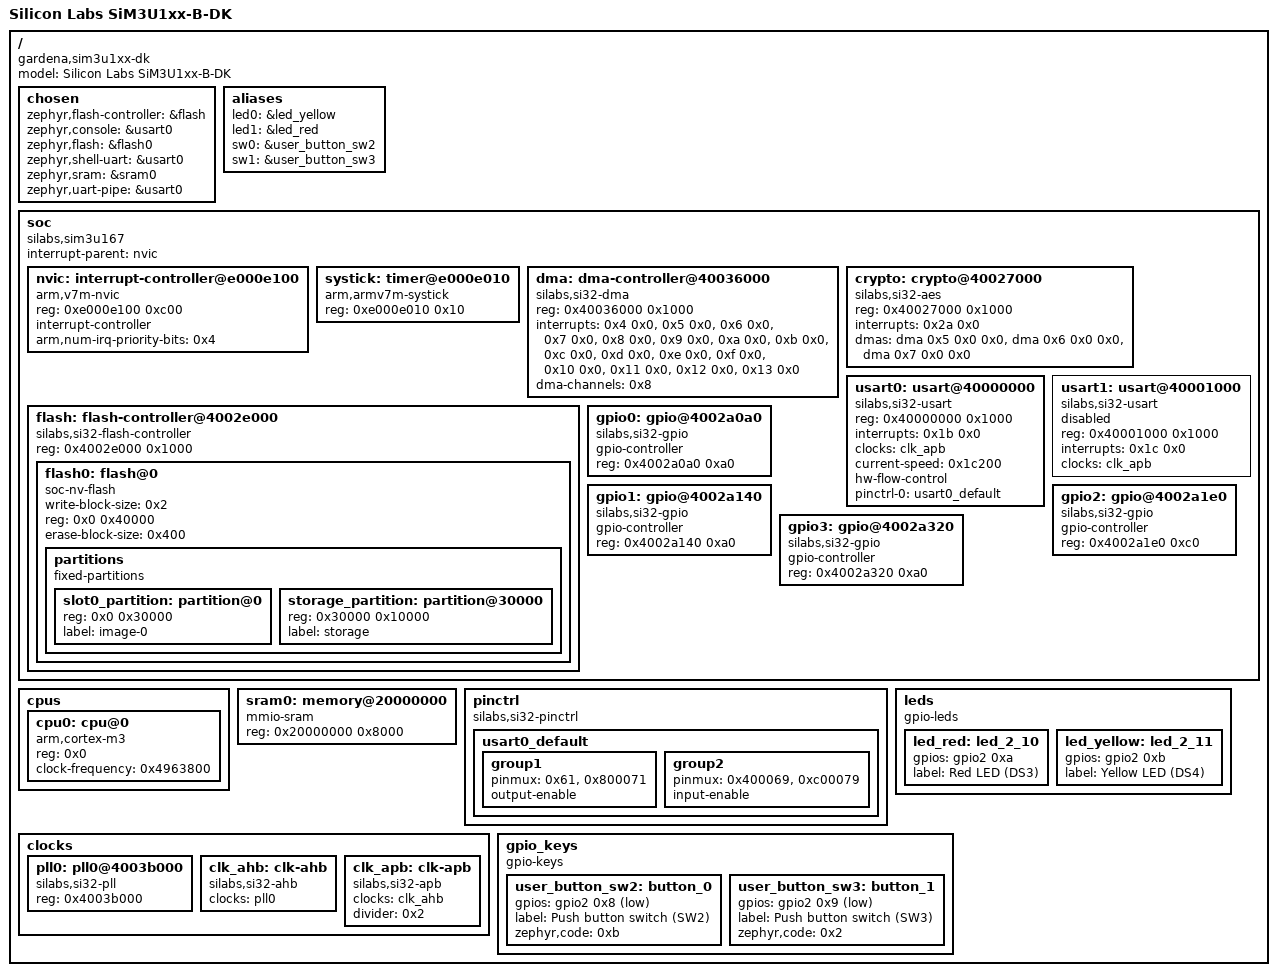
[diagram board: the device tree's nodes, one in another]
/dts-v1/;

/* node '/' defined in zephyr/dts/common/skeleton.dtsi:9 */
/ {
	#address-cells = < 0x1 >;             /* in zephyr/dts/common/skeleton.dtsi:10 */
	#size-cells = < 0x1 >;                /* in zephyr/dts/common/skeleton.dtsi:11 */
	model = "Silicon Labs SiM3U1xx-B-DK"; /* in zephyr/boards/silabs/dev_kits/sim3u1xx_dk/sim3u1xx_dk.dts:13 */
	compatible = "gardena,sim3u1xx-dk",
	             "silabs,sim3u167",
	             "silabs,sim3u";          /* in zephyr/boards/silabs/dev_kits/sim3u1xx_dk/sim3u1xx_dk.dts:14 */

	/* node '/chosen' defined in zephyr/dts/common/skeleton.dtsi:13 */
	chosen {
		zephyr,flash-controller = &flash; /* in zephyr/dts/arm/silabs/sim3u.dtsi:13 */
		zephyr,console = &usart0;         /* in zephyr/boards/silabs/dev_kits/sim3u1xx_dk/sim3u1xx_dk.dts:24 */
		zephyr,flash = &flash0;           /* in zephyr/boards/silabs/dev_kits/sim3u1xx_dk/sim3u1xx_dk.dts:25 */
		zephyr,shell-uart = &usart0;      /* in zephyr/boards/silabs/dev_kits/sim3u1xx_dk/sim3u1xx_dk.dts:26 */
		zephyr,sram = &sram0;             /* in zephyr/boards/silabs/dev_kits/sim3u1xx_dk/sim3u1xx_dk.dts:27 */
		zephyr,uart-pipe = &usart0;       /* in zephyr/boards/silabs/dev_kits/sim3u1xx_dk/sim3u1xx_dk.dts:28 */
	};

	/* node '/aliases' defined in zephyr/dts/common/skeleton.dtsi:15 */
	aliases {
		led0 = &led_yellow;     /* in zephyr/boards/silabs/dev_kits/sim3u1xx_dk/sim3u1xx_dk.dts:17 */
		led1 = &led_red;        /* in zephyr/boards/silabs/dev_kits/sim3u1xx_dk/sim3u1xx_dk.dts:18 */
		sw0 = &user_button_sw2; /* in zephyr/boards/silabs/dev_kits/sim3u1xx_dk/sim3u1xx_dk.dts:19 */
		sw1 = &user_button_sw3; /* in zephyr/boards/silabs/dev_kits/sim3u1xx_dk/sim3u1xx_dk.dts:20 */
	};

	/* node '/soc' defined in zephyr/dts/arm/armv7-m.dtsi:6 */
	soc {
		#address-cells = < 0x1 >;       /* in zephyr/dts/arm/armv7-m.dtsi:7 */
		#size-cells = < 0x1 >;          /* in zephyr/dts/arm/armv7-m.dtsi:8 */
		interrupt-parent = < &nvic >;   /* in zephyr/dts/arm/armv7-m.dtsi:10 */
		ranges;                         /* in zephyr/dts/arm/armv7-m.dtsi:11 */
		compatible = "silabs,sim3u167",
		             "silabs,sim3u",
		             "silabs,sim3",
		             "simple-bus";      /* in zephyr/dts/arm/silabs/sim3u167.dtsi:12 */

		/* node '/soc/interrupt-controller@e000e100' defined in zephyr/dts/arm/armv7-m.dtsi:13 */
		nvic: interrupt-controller@e000e100 {
			#address-cells = < 0x1 >;            /* in zephyr/dts/arm/armv7-m.dtsi:14 */
			compatible = "arm,v7m-nvic";         /* in zephyr/dts/arm/armv7-m.dtsi:15 */
			reg = < 0xe000e100 0xc00 >;          /* in zephyr/dts/arm/armv7-m.dtsi:16 */
			interrupt-controller;                /* in zephyr/dts/arm/armv7-m.dtsi:17 */
			#interrupt-cells = < 0x2 >;          /* in zephyr/dts/arm/armv7-m.dtsi:18 */
			arm,num-irq-priority-bits = < 0x4 >; /* in zephyr/dts/arm/silabs/sim3u.dtsi:147 */
			phandle = < 0x1 >;                   /* in zephyr/dts/arm/armv7-m.dtsi:10 */
		};

		/* node '/soc/timer@e000e010' defined in zephyr/dts/arm/armv7-m.dtsi:21 */
		systick: timer@e000e010 {
			compatible = "arm,armv7m-systick"; /* in zephyr/dts/arm/armv7-m.dtsi:22 */
			reg = < 0xe000e010 0x10 >;         /* in zephyr/dts/arm/armv7-m.dtsi:23 */
		};

		/* node '/soc/dma-controller@40036000' defined in zephyr/dts/arm/silabs/sim3u.dtsi:64 */
		dma: dma-controller@40036000 {
			compatible = "silabs,si32-dma"; /* in zephyr/dts/arm/silabs/sim3u.dtsi:65 */
			reg = < 0x40036000 0x1000 >;    /* in zephyr/dts/arm/silabs/sim3u.dtsi:66 */
			interrupts = < 0x4 0x0 >,
			             < 0x5 0x0 >,
			             < 0x6 0x0 >,
			             < 0x7 0x0 >,
			             < 0x8 0x0 >,
			             < 0x9 0x0 >,
			             < 0xa 0x0 >,
			             < 0xb 0x0 >,
			             < 0xc 0x0 >,
			             < 0xd 0x0 >,
			             < 0xe 0x0 >,
			             < 0xf 0x0 >,
			             < 0x10 0x0 >,
			             < 0x11 0x0 >,
			             < 0x12 0x0 >,
			             < 0x13 0x0 >;      /* in zephyr/dts/arm/silabs/sim3u.dtsi:67 */
			#dma-cells = < 0x3 >;           /* in zephyr/dts/arm/silabs/sim3u.dtsi:72 */
			dma-channels = < 0x8 >;         /* in zephyr/boards/silabs/dev_kits/sim3u1xx_dk/sim3u1xx_dk.dts:117 */
			status = "okay";                /* in zephyr/boards/silabs/dev_kits/sim3u1xx_dk/sim3u1xx_dk.dts:118 */
			phandle = < 0x2 >;              /* in zephyr/dts/arm/silabs/sim3u.dtsi:80 */
		};

		/* node '/soc/crypto@40027000' defined in zephyr/dts/arm/silabs/sim3u.dtsi:76 */
		crypto: crypto@40027000 {
			compatible = "silabs,si32-aes"; /* in zephyr/dts/arm/silabs/sim3u.dtsi:77 */
			reg = < 0x40027000 0x1000 >;    /* in zephyr/dts/arm/silabs/sim3u.dtsi:78 */
			interrupts = < 0x2a 0x0 >;      /* in zephyr/dts/arm/silabs/sim3u.dtsi:79 */
			dmas = < &dma 0x5 0x0 0x0 >,
			       < &dma 0x6 0x0 0x0 >,
			       < &dma 0x7 0x0 0x0 >;    /* in zephyr/dts/arm/silabs/sim3u.dtsi:80 */
			dma-names = "tx",
			            "rx",
			            "xor";              /* in zephyr/dts/arm/silabs/sim3u.dtsi:83 */
			status = "okay";                /* in zephyr/boards/silabs/dev_kits/sim3u1xx_dk/sim3u1xx_dk.dts:122 */
		};

		/* node '/soc/flash-controller@4002e000' defined in zephyr/dts/arm/silabs/sim3u.dtsi:87 */
		flash: flash-controller@4002e000 {
			compatible = "silabs,si32-flash-controller"; /* in zephyr/dts/arm/silabs/sim3u.dtsi:88 */
			reg = < 0x4002e000 0x1000 >;                 /* in zephyr/dts/arm/silabs/sim3u.dtsi:89 */
			#address-cells = < 0x1 >;                    /* in zephyr/dts/arm/silabs/sim3u.dtsi:91 */
			#size-cells = < 0x1 >;                       /* in zephyr/dts/arm/silabs/sim3u.dtsi:92 */

			/* node '/soc/flash-controller@4002e000/flash@0' defined in zephyr/dts/arm/silabs/sim3u.dtsi:94 */
			flash0: flash@0 {
				compatible = "soc-nv-flash";  /* in zephyr/dts/arm/silabs/sim3u.dtsi:95 */
				write-block-size = < 0x2 >;   /* in zephyr/dts/arm/silabs/sim3u.dtsi:96 */
				reg = < 0x0 0x40000 >;        /* in zephyr/dts/arm/silabs/sim3u167.dtsi:17 */
				erase-block-size = < 0x400 >; /* in zephyr/dts/arm/silabs/sim3u167.dtsi:18 */
				status = "okay";              /* in zephyr/boards/silabs/dev_kits/sim3u1xx_dk/sim3u1xx_dk.dts:97 */

				/* node '/soc/flash-controller@4002e000/flash@0/partitions' defined in zephyr/boards/silabs/dev_kits/sim3u1xx_dk/sim3u1xx_dk.dts:99 */
				partitions {
					compatible = "fixed-partitions"; /* in zephyr/boards/silabs/dev_kits/sim3u1xx_dk/sim3u1xx_dk.dts:100 */
					#address-cells = < 0x1 >;        /* in zephyr/boards/silabs/dev_kits/sim3u1xx_dk/sim3u1xx_dk.dts:101 */
					#size-cells = < 0x1 >;           /* in zephyr/boards/silabs/dev_kits/sim3u1xx_dk/sim3u1xx_dk.dts:102 */

					/* node '/soc/flash-controller@4002e000/flash@0/partitions/partition@0' defined in zephyr/boards/silabs/dev_kits/sim3u1xx_dk/sim3u1xx_dk.dts:104 */
					slot0_partition: partition@0 {
						reg = < 0x0 0x30000 >; /* in zephyr/boards/silabs/dev_kits/sim3u1xx_dk/sim3u1xx_dk.dts:105 */
						label = "image-0";     /* in zephyr/boards/silabs/dev_kits/sim3u1xx_dk/sim3u1xx_dk.dts:106 */
					};

					/* node '/soc/flash-controller@4002e000/flash@0/partitions/partition@30000' defined in zephyr/boards/silabs/dev_kits/sim3u1xx_dk/sim3u1xx_dk.dts:109 */
					storage_partition: partition@30000 {
						reg = < 0x30000 0x10000 >; /* in zephyr/boards/silabs/dev_kits/sim3u1xx_dk/sim3u1xx_dk.dts:110 */
						label = "storage";         /* in zephyr/boards/silabs/dev_kits/sim3u1xx_dk/sim3u1xx_dk.dts:111 */
					};
				};
			};
		};

		/* node '/soc/usart@40000000' defined in zephyr/dts/arm/silabs/sim3u.dtsi:100 */
		usart0: usart@40000000 {
			compatible = "silabs,si32-usart"; /* in zephyr/dts/arm/silabs/sim3u.dtsi:101 */
			reg = < 0x40000000 0x1000 >;      /* in zephyr/dts/arm/silabs/sim3u.dtsi:102 */
			interrupts = < 0x1b 0x0 >;        /* in zephyr/dts/arm/silabs/sim3u.dtsi:103 */
			clocks = < &clk_apb >;            /* in zephyr/dts/arm/silabs/sim3u.dtsi:104 */
			current-speed = < 0x1c200 >;      /* in zephyr/boards/silabs/dev_kits/sim3u1xx_dk/sim3u1xx_dk.dts:81 */
			hw-flow-control;                  /* in zephyr/boards/silabs/dev_kits/sim3u1xx_dk/sim3u1xx_dk.dts:82 */
			pinctrl-0 = < &usart0_default >;  /* in zephyr/boards/silabs/dev_kits/sim3u1xx_dk/sim3u1xx_dk.dts:83 */
			pinctrl-names = "default";        /* in zephyr/boards/silabs/dev_kits/sim3u1xx_dk/sim3u1xx_dk.dts:84 */
			status = "okay";                  /* in zephyr/boards/silabs/dev_kits/sim3u1xx_dk/sim3u1xx_dk.dts:85 */
		};

		/* node '/soc/usart@40001000' defined in zephyr/dts/arm/silabs/sim3u.dtsi:108 */
		usart1: usart@40001000 {
			compatible = "silabs,si32-usart"; /* in zephyr/dts/arm/silabs/sim3u.dtsi:109 */
			reg = < 0x40001000 0x1000 >;      /* in zephyr/dts/arm/silabs/sim3u.dtsi:110 */
			interrupts = < 0x1c 0x0 >;        /* in zephyr/dts/arm/silabs/sim3u.dtsi:111 */
			clocks = < &clk_apb >;            /* in zephyr/dts/arm/silabs/sim3u.dtsi:112 */
			status = "disabled";              /* in zephyr/dts/arm/silabs/sim3u.dtsi:113 */
		};

		/* node '/soc/gpio@4002a0a0' defined in zephyr/dts/arm/silabs/sim3u.dtsi:116 */
		gpio0: gpio@4002a0a0 {
			compatible = "silabs,si32-gpio"; /* in zephyr/dts/arm/silabs/sim3u.dtsi:117 */
			gpio-controller;                 /* in zephyr/dts/arm/silabs/sim3u.dtsi:118 */
			#gpio-cells = < 0x2 >;           /* in zephyr/dts/arm/silabs/sim3u.dtsi:119 */
			reg = < 0x4002a0a0 0xa0 >;       /* in zephyr/dts/arm/silabs/sim3u.dtsi:120 */
			status = "okay";                 /* in zephyr/boards/silabs/dev_kits/sim3u1xx_dk/sim3u1xx_dk.dts:89 */
		};

		/* node '/soc/gpio@4002a140' defined in zephyr/dts/arm/silabs/sim3u.dtsi:123 */
		gpio1: gpio@4002a140 {
			compatible = "silabs,si32-gpio"; /* in zephyr/dts/arm/silabs/sim3u.dtsi:124 */
			gpio-controller;                 /* in zephyr/dts/arm/silabs/sim3u.dtsi:125 */
			#gpio-cells = < 0x2 >;           /* in zephyr/dts/arm/silabs/sim3u.dtsi:126 */
			reg = < 0x4002a140 0xa0 >;       /* in zephyr/dts/arm/silabs/sim3u.dtsi:127 */
		};

		/* node '/soc/gpio@4002a1e0' defined in zephyr/dts/arm/silabs/sim3u.dtsi:130 */
		gpio2: gpio@4002a1e0 {
			compatible = "silabs,si32-gpio"; /* in zephyr/dts/arm/silabs/sim3u.dtsi:131 */
			gpio-controller;                 /* in zephyr/dts/arm/silabs/sim3u.dtsi:132 */
			#gpio-cells = < 0x2 >;           /* in zephyr/dts/arm/silabs/sim3u.dtsi:133 */
			reg = < 0x4002a1e0 0xc0 >;       /* in zephyr/dts/arm/silabs/sim3u.dtsi:134 */
			status = "okay";                 /* in zephyr/boards/silabs/dev_kits/sim3u1xx_dk/sim3u1xx_dk.dts:93 */
			phandle = < 0x7 >;               /* in zephyr/boards/silabs/dev_kits/sim3u1xx_dk/sim3u1xx_dk.dts:35 */
		};

		/* node '/soc/gpio@4002a320' defined in zephyr/dts/arm/silabs/sim3u.dtsi:137 */
		gpio3: gpio@4002a320 {
			compatible = "silabs,si32-gpio"; /* in zephyr/dts/arm/silabs/sim3u.dtsi:138 */
			gpio-controller;                 /* in zephyr/dts/arm/silabs/sim3u.dtsi:139 */
			#gpio-cells = < 0x2 >;           /* in zephyr/dts/arm/silabs/sim3u.dtsi:140 */
			reg = < 0x4002a320 0xa0 >;       /* in zephyr/dts/arm/silabs/sim3u.dtsi:141 */
		};
	};

	/* node '/cpus' defined in zephyr/dts/arm/silabs/sim3u.dtsi:16 */
	cpus {
		#address-cells = < 0x1 >; /* in zephyr/dts/arm/silabs/sim3u.dtsi:17 */
		#size-cells = < 0x0 >;    /* in zephyr/dts/arm/silabs/sim3u.dtsi:18 */

		/* node '/cpus/cpu@0' defined in zephyr/dts/arm/silabs/sim3u.dtsi:20 */
		cpu0: cpu@0 {
			compatible = "arm,cortex-m3";    /* in zephyr/dts/arm/silabs/sim3u.dtsi:21 */
			device_type = "cpu";             /* in zephyr/dts/arm/silabs/sim3u.dtsi:22 */
			reg = < 0x0 >;                   /* in zephyr/dts/arm/silabs/sim3u.dtsi:24 */
			clock-frequency = < 0x4963800 >; /* in zephyr/boards/silabs/dev_kits/sim3u1xx_dk/sim3u1xx_dk.dts:63 */
		};
	};

	/* node '/memory@20000000' defined in zephyr/dts/arm/silabs/sim3u.dtsi:28 */
	sram0: memory@20000000 {
		compatible = "mmio-sram";    /* in zephyr/dts/arm/silabs/sim3u.dtsi:29 */
		reg = < 0x20000000 0x8000 >; /* in zephyr/dts/arm/silabs/sim3u167.dtsi:22 */
	};

	/* node '/pinctrl' defined in zephyr/dts/arm/silabs/sim3u.dtsi:32 */
	pinctrl: pinctrl {
		compatible = "silabs,si32-pinctrl"; /* in zephyr/dts/arm/silabs/sim3u.dtsi:33 */
		status = "okay";                    /* in zephyr/dts/arm/silabs/sim3u.dtsi:34 */

		/* node '/pinctrl/usart0_default' defined in zephyr/boards/silabs/dev_kits/sim3u1xx_dk/sim3u1xx_dk-pinctrl.dtsi:10 */
		usart0_default: usart0_default {
			phandle = < 0x4 >; /* in zephyr/boards/silabs/dev_kits/sim3u1xx_dk/sim3u1xx_dk.dts:83 */

			/* node '/pinctrl/usart0_default/group1' defined in zephyr/boards/silabs/dev_kits/sim3u1xx_dk/sim3u1xx_dk-pinctrl.dtsi:11 */
			group1 {
				pinmux = < 0x61 >,
				         < 0x800071 >; /* in zephyr/boards/silabs/dev_kits/sim3u1xx_dk/sim3u1xx_dk-pinctrl.dtsi:12 */
				output-enable;         /* in zephyr/boards/silabs/dev_kits/sim3u1xx_dk/sim3u1xx_dk-pinctrl.dtsi:14 */
			};

			/* node '/pinctrl/usart0_default/group2' defined in zephyr/boards/silabs/dev_kits/sim3u1xx_dk/sim3u1xx_dk-pinctrl.dtsi:17 */
			group2 {
				pinmux = < 0x400069 >,
				         < 0xc00079 >; /* in zephyr/boards/silabs/dev_kits/sim3u1xx_dk/sim3u1xx_dk-pinctrl.dtsi:18 */
				input-enable;          /* in zephyr/boards/silabs/dev_kits/sim3u1xx_dk/sim3u1xx_dk-pinctrl.dtsi:20 */
			};
		};
	};

	/* node '/clocks' defined in zephyr/dts/arm/silabs/sim3u.dtsi:37 */
	clocks {
		#address-cells = < 0x1 >; /* in zephyr/dts/arm/silabs/sim3u.dtsi:38 */
		#size-cells = < 0x0 >;    /* in zephyr/dts/arm/silabs/sim3u.dtsi:39 */

		/* node '/clocks/pll0@4003b000' defined in zephyr/dts/arm/silabs/sim3u.dtsi:41 */
		pll0: pll0@4003b000 {
			compatible = "silabs,si32-pll"; /* in zephyr/dts/arm/silabs/sim3u.dtsi:42 */
			#clock-cells = < 0x0 >;         /* in zephyr/dts/arm/silabs/sim3u.dtsi:43 */
			reg = < 0x4003b000 >;           /* in zephyr/dts/arm/silabs/sim3u.dtsi:44 */
			status = "okay";                /* in zephyr/boards/silabs/dev_kits/sim3u1xx_dk/sim3u1xx_dk.dts:67 */
			phandle = < 0x5 >;              /* in zephyr/boards/silabs/dev_kits/sim3u1xx_dk/sim3u1xx_dk.dts:71 */
		};

		/* node '/clocks/clk-ahb' defined in zephyr/dts/arm/silabs/sim3u.dtsi:48 */
		clk_ahb: clk-ahb {
			compatible = "silabs,si32-ahb"; /* in zephyr/dts/arm/silabs/sim3u.dtsi:49 */
			#clock-cells = < 0x0 >;         /* in zephyr/dts/arm/silabs/sim3u.dtsi:50 */
			clocks = < &pll0 >;             /* in zephyr/boards/silabs/dev_kits/sim3u1xx_dk/sim3u1xx_dk.dts:71 */
			status = "okay";                /* in zephyr/boards/silabs/dev_kits/sim3u1xx_dk/sim3u1xx_dk.dts:72 */
			phandle = < 0x6 >;              /* in zephyr/dts/arm/silabs/sim3u.dtsi:58 */
		};

		/* node '/clocks/clk-apb' defined in zephyr/dts/arm/silabs/sim3u.dtsi:54 */
		clk_apb: clk-apb {
			compatible = "silabs,si32-apb"; /* in zephyr/dts/arm/silabs/sim3u.dtsi:55 */
			#clock-cells = < 0x0 >;         /* in zephyr/dts/arm/silabs/sim3u.dtsi:56 */
			clocks = < &clk_ahb >;          /* in zephyr/dts/arm/silabs/sim3u.dtsi:58 */
			divider = < 0x2 >;              /* in zephyr/boards/silabs/dev_kits/sim3u1xx_dk/sim3u1xx_dk.dts:76 */
			status = "okay";                /* in zephyr/boards/silabs/dev_kits/sim3u1xx_dk/sim3u1xx_dk.dts:77 */
			phandle = < 0x3 >;              /* in zephyr/dts/arm/silabs/sim3u.dtsi:104 */
		};
	};

	/* node '/leds' defined in zephyr/boards/silabs/dev_kits/sim3u1xx_dk/sim3u1xx_dk.dts:31 */
	leds {
		compatible = "gpio-leds"; /* in zephyr/boards/silabs/dev_kits/sim3u1xx_dk/sim3u1xx_dk.dts:32 */

		/* node '/leds/led_2_10' defined in zephyr/boards/silabs/dev_kits/sim3u1xx_dk/sim3u1xx_dk.dts:34 */
		led_red: led_2_10 {
			gpios = < &gpio2 0xa 0x0 >; /* in zephyr/boards/silabs/dev_kits/sim3u1xx_dk/sim3u1xx_dk.dts:35 */
			label = "Red LED (DS3)";    /* in zephyr/boards/silabs/dev_kits/sim3u1xx_dk/sim3u1xx_dk.dts:36 */
		};

		/* node '/leds/led_2_11' defined in zephyr/boards/silabs/dev_kits/sim3u1xx_dk/sim3u1xx_dk.dts:39 */
		led_yellow: led_2_11 {
			gpios = < &gpio2 0xb 0x0 >; /* in zephyr/boards/silabs/dev_kits/sim3u1xx_dk/sim3u1xx_dk.dts:40 */
			label = "Yellow LED (DS4)"; /* in zephyr/boards/silabs/dev_kits/sim3u1xx_dk/sim3u1xx_dk.dts:41 */
		};
	};

	/* node '/gpio_keys' defined in zephyr/boards/silabs/dev_kits/sim3u1xx_dk/sim3u1xx_dk.dts:45 */
	gpio_keys {
		compatible = "gpio-keys"; /* in zephyr/boards/silabs/dev_kits/sim3u1xx_dk/sim3u1xx_dk.dts:46 */

		/* node '/gpio_keys/button_0' defined in zephyr/boards/silabs/dev_kits/sim3u1xx_dk/sim3u1xx_dk.dts:48 */
		user_button_sw2: button_0 {
			gpios = < &gpio2 0x8 0x11 >;        /* in zephyr/boards/silabs/dev_kits/sim3u1xx_dk/sim3u1xx_dk.dts:49 */
			label = "Push button switch (SW2)"; /* in zephyr/boards/silabs/dev_kits/sim3u1xx_dk/sim3u1xx_dk.dts:50 */
			zephyr,code = < 0xb >;              /* in zephyr/boards/silabs/dev_kits/sim3u1xx_dk/sim3u1xx_dk.dts:51 */
		};

		/* node '/gpio_keys/button_1' defined in zephyr/boards/silabs/dev_kits/sim3u1xx_dk/sim3u1xx_dk.dts:54 */
		user_button_sw3: button_1 {
			gpios = < &gpio2 0x9 0x11 >;        /* in zephyr/boards/silabs/dev_kits/sim3u1xx_dk/sim3u1xx_dk.dts:55 */
			label = "Push button switch (SW3)"; /* in zephyr/boards/silabs/dev_kits/sim3u1xx_dk/sim3u1xx_dk.dts:56 */
			zephyr,code = < 0x2 >;              /* in zephyr/boards/silabs/dev_kits/sim3u1xx_dk/sim3u1xx_dk.dts:57 */
		};
	};
};
